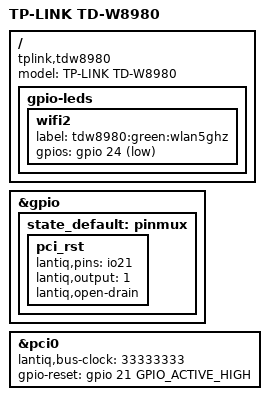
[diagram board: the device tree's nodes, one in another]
/dts-v1/;

#include "TDW89X0.dtsi"

/ {
	compatible = "tplink,tdw8980", "tplink,tdw89x0", "lantiq,xway", "lantiq,vr9";
	model = "TP-LINK TD-W8980";

	gpio-leds {
		wifi2 {
			label = "tdw8980:green:wlan5ghz";
			gpios = <&gpio 24 GPIO_ACTIVE_LOW>;
		};
	};
};

&gpio {
	state_default: pinmux {
		pci_rst {
			lantiq,pins = "io21";
			lantiq,output = <1>;
			lantiq,open-drain;
		};
	};
};

&pci0 {
	status = "okay";
	lantiq,bus-clock = <33333333>;
	gpio-reset = <&gpio 21 GPIO_ACTIVE_HIGH>;
};
